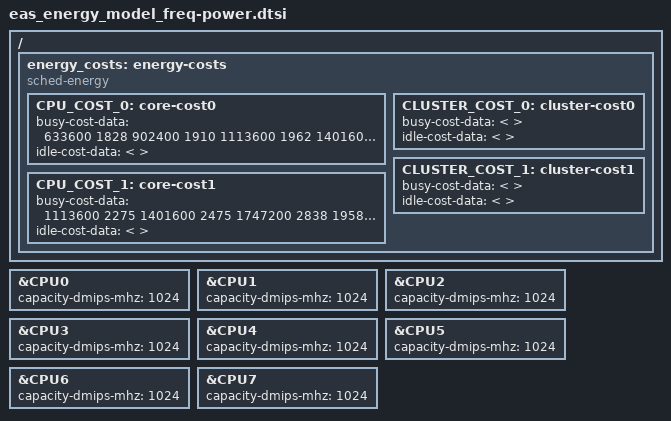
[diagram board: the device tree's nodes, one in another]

&CPU0 {
	capacity-dmips-mhz = <1024>;
};

&CPU1 {
	capacity-dmips-mhz = <1024>;
};

&CPU2 {
	capacity-dmips-mhz = <1024>;
};

&CPU3 {
	capacity-dmips-mhz = <1024>;
};

&CPU4 {
	capacity-dmips-mhz = <1024>;
};

&CPU5 {
	capacity-dmips-mhz = <1024>;
};

&CPU6 {
	capacity-dmips-mhz = <1024>;
};

&CPU7 {
	capacity-dmips-mhz = <1024>;
};

/ {
	energy_costs: energy-costs {
		compatible = "sched-energy";

		CPU_COST_0: core-cost0 {
			busy-cost-data = <
				 633600 1828
				 902400 1910
				1113600 1962
				1401600 2055
				1536000 2112
				1747200 2222
				1843200 2266
			>;
			idle-cost-data = <
				
			>;
		};

		CPU_COST_1: core-cost1 {
			busy-cost-data = <
				1113600 2275
				1401600 2475
				1747200 2838
				1958400 3172
				2150400 3410
				2208000 3696
			>;
			idle-cost-data = <
				
			>;
		};

		CLUSTER_COST_0: cluster-cost0 {
			busy-cost-data = <
			>;
			idle-cost-data = <
				
			>;
		};

		CLUSTER_COST_1: cluster-cost1 {
			busy-cost-data = <
			>;
			idle-cost-data = <
				
			>;
		};
	}; /* energy-costs */
};
